# RSTCTL_356.0 register map
Vendor: Texas Instruments
Peripheral module from a debugger description file (folder MSP432).
Registers are 32-bit, read-write, no defined reset value unless marked. A register's access mark holds for its fields unless they carry their own. Offsets are as the file gives them; lines under a group give offsets from that group; [hi:lo] are bit positions; {n}, {i} and the like mark numbered series; 'fields as' and 'values as' point back to an identical list; <NAME> marks a mode.

## RSTCTL
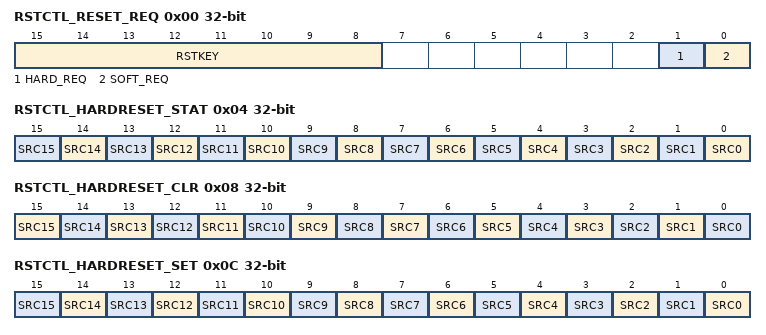
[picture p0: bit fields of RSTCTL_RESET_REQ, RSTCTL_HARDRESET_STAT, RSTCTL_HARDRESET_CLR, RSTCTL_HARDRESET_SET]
0x00 RSTCTL_RESET_REQ — Reset Request Register
  [15:8] RSTKEY — Write key to unlock reset request bits
  [1] HARD_REQ — Hard Reset request
  [0] SOFT_REQ — Soft Reset request
0x04 RSTCTL_HARDRESET_STAT ro — Hard Reset Status Register
  [n] SRC{n} (n=0..15) — Indicates that SRC{n} was the source of the Hard Reset
0x08 RSTCTL_HARDRESET_CLR — Hard Reset Status Clear Register
  [15] SRC15 — Write 1 clears the corresponding bit in the RSTCTL_HRDRESETSTAT_REG
  [n] SRC{n} (n=0..14) — Write 1 clears the corresponding bit in the RSTCTL_HARDRESET_STAT
0x0C RSTCTL_HARDRESET_SET — Hard Reset Status Set Register
  [n] SRC{n} (n=0..15) — Write 1 sets the corresponding bit in the RSTCTL_HARDRESET_STAT (and initiates a Hard Reset)
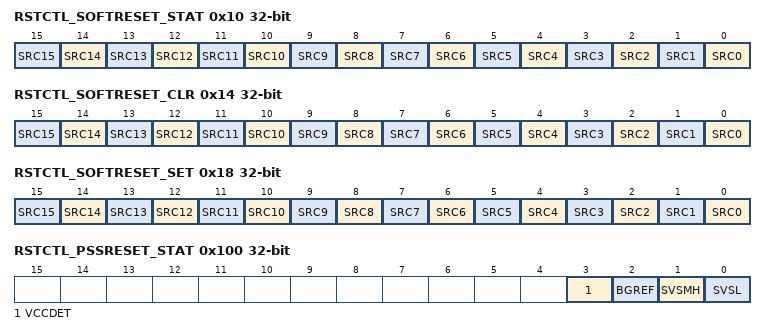
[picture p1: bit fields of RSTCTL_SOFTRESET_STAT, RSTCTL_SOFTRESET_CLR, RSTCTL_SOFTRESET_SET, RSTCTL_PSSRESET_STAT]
0x10 RSTCTL_SOFTRESET_STAT ro — Soft Reset Status Register
  [n] SRC{n} (n=0..15) — If 1, indicates that SRC{n} was the source of the Soft Reset
0x14 RSTCTL_SOFTRESET_CLR — Soft Reset Status Clear Register
  [n] SRC{n} (n=0..15) — Write 1 clears the corresponding bit in the RSTCTL_SOFTRESET_STAT
0x18 RSTCTL_SOFTRESET_SET — Soft Reset Status Set Register
  [n] SRC{n} (n=0..15) — Write 1 sets the corresponding bit in the RSTCTL_SOFTRESET_STAT (and initiates a Soft Reset)
0x100 RSTCTL_PSSRESET_STAT ro — PSS Reset Status Register
  [3] VCCDET — Indicates if POR was caused by a VCCDET trip condition in the PSS
  [2] BGREF — Indicates if POR was caused by a BGREF not okay condition in the PSS
  [1] SVSMH — Indicates if POR was caused by an SVSMH trip condition int the PSS
  [0] SVSL — Indicates if POR was caused by an SVSL trip condition in the PSS
0x104 RSTCTL_PSSRESET_CLR — PSS Reset Status Clear Register
  [0] CLR — Write 1 clears all PSS Reset Flags in the RSTCTL_PSSRESET_STAT
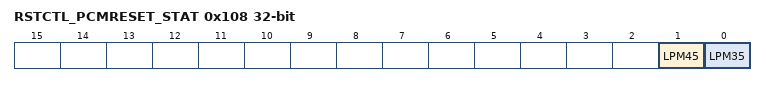
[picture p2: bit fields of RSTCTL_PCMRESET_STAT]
0x108 RSTCTL_PCMRESET_STAT ro — PCM Reset Status Register
  [1] LPM45 — Indicates if POR was caused by PCM due to an exit from LPM4.5
  [0] LPM35 — Indicates if POR was caused by PCM due to an exit from LPM3.5
0x10C RSTCTL_PCMRESET_CLR — PCM Reset Status Clear Register
  [0] CLR — Write 1 clears all PCM Reset Flags in the RSTCTL_PCMRESET_STAT
0x110 RSTCTL_PINRESET_STAT ro — Pin Reset Status Register
  [0] RSTNMI — POR was caused by RSTn/NMI pin based reset event
0x114 RSTCTL_PINRESET_CLR — Pin Reset Status Clear Register
  [0] CLR — Write 1 clears the RSTn/NMI Pin Reset Flag in RSTCTL_PINRESET_STAT
0x118 RSTCTL_REBOOTRESET_STAT ro — Reboot Reset Status Register
  [0] REBOOT — Indicates if Reboot reset was caused by the SYSCTL module.
0x11C RSTCTL_REBOOTRESET_CLR — Reboot Reset Status Clear Register
  [0] CLR — Write 1 clears the Reboot Reset Flag in RSTCTL_REBOOTRESET_STAT
0x120 RSTCTL_CSRESET_STAT ro — CS Reset Status Register
  [0] DCOR_SHT — Indicates if POR was caused by DCO short circuit fault in the external resistor mode
0x124 RSTCTL_CSRESET_CLR — CS Reset Status Clear Register
  [0] CLR — Write 1 clears the DCOR_SHT Flag in RSTCTL_CSRESET_STAT as well as DCOR_SHTIFG flag in CSIFG register of clock system
